# ESP32-S2 register map
Vendor: ESPRESSIF SYSTEMS (SHANGHAI) CO., LTD.; Series: ESP32 S-Series; File version: 20
CPU: Xtensa LX7 r0p0, little endian, no MPU, no FPU, 0 interrupt priority bits
Address unit: 32 bits
Registers are 32-bit, read-write, reset 0x0 unless marked. A register's access mark holds for its fields unless they carry their own. Offsets are from the block's base; [hi:lo] are bit positions; {n}, {i} and the like mark numbered series.

## INTERRUPT_CORE0 — Interrupt Controller (Core 0)
Base 0x3F4C2000
{0x0+4i} CORE_0_INTR_MAP{i} (i=0..94)
  [4:0] MAP
{0x17C+4i} CORE_0_INTR_STATUS{i} (i=0..2) ro — Interrupt status register {i}
  [31:0] PRO_INTR_STATUS_0 — This register stores the status of the first 32 input interrupt sources.
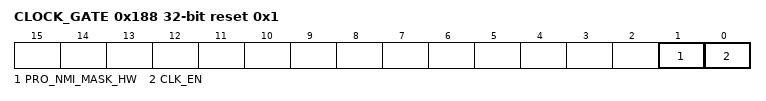
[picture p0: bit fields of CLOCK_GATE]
0x188 CLOCK_GATE reset 0x1 — NMI interrupt signals mask register
  [1] PRO_NMI_MASK_HW — This bit is used to disable all NMI interrupt signals to CPU.
  [0] CLK_EN — This bit is used to enable or disable the clock of interrupt matrix. 1: enable the clock. 0: disable the clock.
0xFFC REG_DATE — Version control register

## IO_MUX — Input/Output Multiplexer
Base 0x3F409000
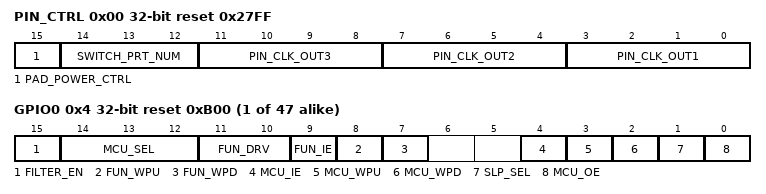
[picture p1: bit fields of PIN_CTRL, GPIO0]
0x00 PIN_CTRL reset 0x27FF — Clock output configuration register
  [15] PAD_POWER_CTRL — Select power voltage for GPIO33 ~ GPIO37. 1: select VDD_SPI 1.8 V. 0: select VDD3P3_CPU 3.3 V.
  [14:12] SWITCH_PRT_NUM — IO pin power switch delay, delay unit is one APB clock.
  [11:8] PIN_CLK_OUT3 — Configure I2S0 clock output. 0: output I2S0 clock to CLK_OUT3. 15: disabled.
  [7:4] PIN_CLK_OUT2 — Configure I2S0 clock output. 0: output I2S0 clock to CLK_OUT2. 15: disabled.
  [3:0] PIN_CLK_OUT1 — Configure I2S0 clock output. 0: output I2S0 clock to CLK_OUT1. 15: disabled.
{0x4+4i} GPIO{i} (i=0..46) reset 0xB00 — Configuration register for pin GPIO{i}
  [15] FILTER_EN — Enable filter for pin input signals. 1: Filter enabled. 2: Filter disabled.
  [14:12] MCU_SEL — Select IO MUX function for this signal. 0: Select Function 1. 1: Select Function 2, etc.
  [11:10] FUN_DRV — Select the drive strength of the pin. 0: ~5 mA. 1: ~10 mA. 2: ~20 mA. 3: ~40 mA.
  [9] FUN_IE — Input enable of the pin. 1: Input enabled. 0: Input disabled.
  [8] FUN_WPU — Pull-up enable of the pin. 1: Internal pull-up enabled. 0: Internal pull-up disabled.
  [7] FUN_WPD — Pull-down enable of the pin. 1: Internal pull-down enabled. 0: internal pull-down disabled.
  [4] MCU_IE — Input enable of the pin during sleep mode. 1: Input enabled. 0: Input disabled.
  [3] MCU_WPU — Pull-up enable of the pin during sleep mode. 1: Internal pull-up enabled. 0: Internal pull-up disabled.
  [2] MCU_WPD — Pull-down enable of the pin during sleep mode. 1: Internal pull-down enabled. 0: internal pull-down disabled.
  [1] SLP_SEL — Sleep mode selection of this pin. Set to 1 to put the pin in sleep mode.
  [0] MCU_OE — Output enable of the pin in sleep mode. 1: Output enabled. 0: Output disabled.
0xFC DATE — Version control register

## RNG — Hardware Random Number Generator
Base 0x60035000
0x110 DATA ro — Random number data

## RSA — RSA (Rivest Shamir Adleman) Accelerator
Base 0x6003C000
{0x0+4i} M_MEM[{i}] (i=0..127) wo — Represents M
{0x200+4i} Z_MEM[{i}] (i=0..127) — Represents Z
{0x400+4i} Y_MEM[{i}] (i=0..127) wo — Represents Y
{0x600+4i} X_MEM[{i}] (i=0..127) wo — Represents X
0x800 M_PRIME — Register to store M'
  [31:0] M_PRIME — Stores M'.
0x804 MODE — RSA length mode
  [6:0] MODE — Stores the mode of modular exponentiation.
0x808 CLEAN ro — RSA clean register
  [0] CLEAN — The content of this bit is 1 when memories complete initialization.
0x80C MODEXP_START wo — Modular exponentiation starting bit
  [0] MODEXP_START — Set this bit to 1 to start the modular exponentiation.
0x810 MODMULT_START wo — Modular multiplication starting bit
  [0] MODMULT_START — Set this bit to 1 to start the modular multiplication.
0x814 MULT_START wo — Normal multiplication starting bit
  [0] MULT_START — Set this bit to 1 to start the multiplication.
0x818 IDLE ro — RSA idle register
  [0] IDLE — The content of this bit is 1 when the RSA accelerator is idle.
0x81C INT_CLR — RSA clear interrupt register
  [0] INT_CLR — Set this bit to 1 to clear the RSA interrupts.
0x820 CONSTANT_TIME reset 0x1 — The constant_time option
  [0] CONSTANT_TIME — Set this bit to 0 to enable the acceleration option of constant_time for modular exponentiation. Set to 1 to disable the acceleration (by default).
0x824 SEARCH_ENABLE — The search option
  [0] SEARCH_ENABLE — Set this bit to 1 to enable the acceleration option of search for modular exponentiation. Set to 0 to disable the acceleration (by default).
0x828 SEARCH_POS — The search position
  [11:0] SEARCH_POS — Is used to configure the starting address when the acceleration option of search is used.
0x82C INT_ENA reset 0x1 — RSA interrupt enable register
  [0] INT_ENA — Set this bit to 1 to enable the RSA interrupt. This option is enabled by default.
0x830 DATE — Version control register
